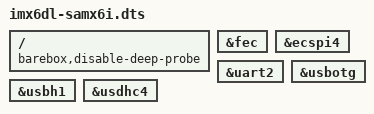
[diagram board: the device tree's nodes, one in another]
// SPDX-License-Identifier: GPL-2.0-or-later
/*
 * Copyright 2018 (C) Pengutronix, Michael Grzeschik <mgr@pengutronix.de>
 * Copyright 2019 (C) Pengutronix, Marco Felsch <kernel@pengutronix.de>
 */

/dts-v1/;
#include <arm/nxp/imx/imx6dl-kontron-samx6i.dtsi>
#include "imx6dl.dtsi"
#include "imx6qdl-smarc-samx6i.dtsi"

/ {
	barebox,disable-deep-probe;
};

&fec {
	status = "okay";
};

&ecspi4 {
	status = "okay";
};

&uart2 {
	status = "okay";
};

&usbotg {
	status = "okay";
};

&usbh1 {
	status = "okay";
};

&usdhc4 {
	status = "okay";
};
